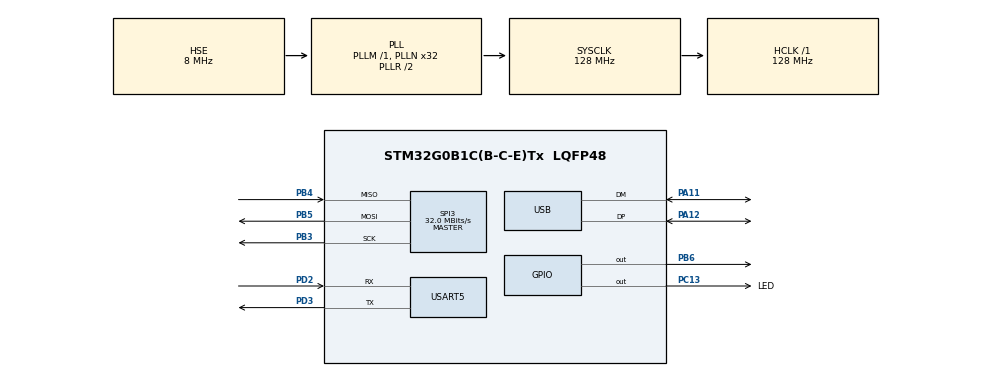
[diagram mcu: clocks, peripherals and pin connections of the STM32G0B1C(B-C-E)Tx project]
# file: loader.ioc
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Dma.MEMTOMEM.3.Direction=DMA_MEMORY_TO_MEMORY
Dma.MEMTOMEM.3.EventEnable=DISABLE
Dma.MEMTOMEM.3.Instance=DMA1_Channel5
Dma.MEMTOMEM.3.MemDataAlignment=DMA_MDATAALIGN_BYTE
Dma.MEMTOMEM.3.MemInc=DMA_MINC_ENABLE
Dma.MEMTOMEM.3.Mode=DMA_NORMAL
Dma.MEMTOMEM.3.PeriphDataAlignment=DMA_PDATAALIGN_BYTE
Dma.MEMTOMEM.3.PeriphInc=DMA_PINC_ENABLE
Dma.MEMTOMEM.3.Polarity=HAL_DMAMUX_REQ_GEN_RISING
Dma.MEMTOMEM.3.Priority=DMA_PRIORITY_LOW
Dma.MEMTOMEM.3.RequestNumber=1
Dma.MEMTOMEM.3.SignalID=NONE
Dma.MEMTOMEM.3.SyncEnable=DISABLE
Dma.MEMTOMEM.3.SyncPolarity=HAL_DMAMUX_SYNC_NO_EVENT
Dma.MEMTOMEM.3.SyncRequestNumber=1
Dma.MEMTOMEM.3.SyncSignalID=NONE
Dma.Request0=SPI3_RX
Dma.Request1=SPI3_TX
Dma.Request2=USART5_RX
Dma.Request3=MEMTOMEM
Dma.SPI3_RX.0.Direction=DMA_PERIPH_TO_MEMORY
Dma.SPI3_RX.0.EventEnable=DISABLE
Dma.SPI3_RX.0.Instance=DMA1_Channel1
Dma.SPI3_RX.0.MemDataAlignment=DMA_MDATAALIGN_BYTE
Dma.SPI3_RX.0.MemInc=DMA_MINC_ENABLE
Dma.SPI3_RX.0.Mode=DMA_NORMAL
Dma.SPI3_RX.0.PeriphDataAlignment=DMA_PDATAALIGN_BYTE
Dma.SPI3_RX.0.PeriphInc=DMA_PINC_DISABLE
Dma.SPI3_RX.0.Polarity=HAL_DMAMUX_REQ_GEN_RISING
Dma.SPI3_RX.0.Priority=DMA_PRIORITY_LOW
Dma.SPI3_RX.0.RequestNumber=1
Dma.SPI3_RX.0.SignalID=NONE
Dma.SPI3_RX.0.SyncEnable=DISABLE
Dma.SPI3_RX.0.SyncPolarity=HAL_DMAMUX_SYNC_NO_EVENT
Dma.SPI3_RX.0.SyncRequestNumber=1
Dma.SPI3_RX.0.SyncSignalID=NONE
Dma.SPI3_TX.1.Direction=DMA_MEMORY_TO_PERIPH
Dma.SPI3_TX.1.EventEnable=DISABLE
Dma.SPI3_TX.1.Instance=DMA1_Channel2
Dma.SPI3_TX.1.MemDataAlignment=DMA_MDATAALIGN_BYTE
Dma.SPI3_TX.1.MemInc=DMA_MINC_ENABLE
Dma.SPI3_TX.1.Mode=DMA_NORMAL
Dma.SPI3_TX.1.PeriphDataAlignment=DMA_PDATAALIGN_BYTE
Dma.SPI3_TX.1.PeriphInc=DMA_PINC_DISABLE
Dma.SPI3_TX.1.Polarity=HAL_DMAMUX_REQ_GEN_RISING
Dma.SPI3_TX.1.Priority=DMA_PRIORITY_LOW
Dma.SPI3_TX.1.RequestNumber=1
Dma.SPI3_TX.1.SignalID=NONE
Dma.SPI3_TX.1.SyncEnable=DISABLE
Dma.SPI3_TX.1.SyncPolarity=HAL_DMAMUX_SYNC_NO_EVENT
Dma.SPI3_TX.1.SyncRequestNumber=1
Dma.SPI3_TX.1.SyncSignalID=NONE
Dma.USART5_RX.2.Direction=DMA_PERIPH_TO_MEMORY
Dma.USART5_RX.2.EventEnable=DISABLE
Dma.USART5_RX.2.Instance=DMA1_Channel3
Dma.USART5_RX.2.MemDataAlignment=DMA_MDATAALIGN_BYTE
Dma.USART5_RX.2.MemInc=DMA_MINC_ENABLE
Dma.USART5_RX.2.Mode=DMA_NORMAL
Dma.USART5_RX.2.PeriphDataAlignment=DMA_PDATAALIGN_BYTE
Dma.USART5_RX.2.PeriphInc=DMA_PINC_DISABLE
Dma.USART5_RX.2.Polarity=HAL_DMAMUX_REQ_GEN_RISING
Dma.USART5_RX.2.Priority=DMA_PRIORITY_LOW
Dma.USART5_RX.2.RequestNumber=1
Dma.USART5_RX.2.SignalID=NONE
Dma.USART5_RX.2.SyncEnable=DISABLE
Dma.USART5_RX.2.SyncPolarity=HAL_DMAMUX_SYNC_NO_EVENT
Dma.USART5_RX.2.SyncRequestNumber=1
Dma.USART5_RX.2.SyncSignalID=NONE
Mcu.Family=STM32G0
Mcu.Name=STM32G0B1C(B-C-E)Tx
Mcu.Package=LQFP48
NVIC.DMA1_Ch4_7_DMA2_Ch1_5_DMAMUX1_OVR_IRQn=true\:0\:0\:false\:false\:true\:false\:true\:true
NVIC.DMA1_Channel1_IRQn=true\:0\:0\:false\:false\:true\:false\:true\:true
NVIC.DMA1_Channel2_3_IRQn=true\:0\:0\:false\:false\:true\:false\:true\:true
NVIC.FLASH_IRQn=true\:0\:0\:false\:false\:true\:true\:true\:true
NVIC.PVD_VDDIO2_IRQn=true\:0\:0\:false\:false\:true\:true\:true\:true
NVIC.RCC_IRQn=true\:0\:0\:false\:false\:true\:true\:false\:true
NVIC.SPI2_3_IRQn=true\:0\:0\:false\:false\:true\:true\:true\:true
NVIC.USART3_4_5_6_LPUART1_IRQn=true\:0\:0\:false\:false\:true\:true\:true\:true
NVIC.USB_UCPD1_2_IRQn=true\:0\:0\:false\:false\:true\:true\:true\:true
PA11\ [PA9].Mode=Device
PA11\ [PA9].Signal=USB_DM
PA12\ [PA10].Mode=Device
PA12\ [PA10].Signal=USB_DP
PA13.Mode=Serial_Wire
PA13.Signal=SYS_SWDIO
PA14-BOOT0.Mode=Serial_Wire
PA14-BOOT0.Signal=SYS_SWCLK
PB3.Mode=Full_Duplex_Master
PB3.Signal=SPI3_SCK
PB4.Mode=Full_Duplex_Master
PB4.Signal=SPI3_MISO
PB5.Mode=Full_Duplex_Master
PB5.Signal=SPI3_MOSI
PB6.PinState=GPIO_PIN_SET
PB6.Signal=GPIO_Output
PC13.GPIO_Label=LED
PC13.PinState=GPIO_PIN_SET
PC13.Signal=GPIO_Output
PC14-OSC32_IN\ (PC14).Mode=LSE-External-Oscillator
PC14-OSC32_IN\ (PC14).Signal=RCC_OSC32_IN
PC15-OSC32_OUT\ (PC15).Mode=LSE-External-Oscillator
PC15-OSC32_OUT\ (PC15).Signal=RCC_OSC32_OUT
PD2.Mode=Asynchronous
PD2.Signal=USART5_RX
PD3.Mode=Asynchronous
PD3.Signal=USART5_TX
PF0-OSC_IN\ (PF0).Mode=HSE-External-Oscillator
PF0-OSC_IN\ (PF0).Signal=RCC_OSC_IN
PF1-OSC_OUT\ (PF1).Mode=HSE-External-Oscillator
PF1-OSC_OUT\ (PF1).Signal=RCC_OSC_OUT
ProjectManager.HeapSize=0x200
ProjectManager.StackSize=0x2000
ProjectManager.TargetToolchain=MDK-ARM V5.32
RCC.ADCFreq_Value=128000000
RCC.AHBFreq_Value=128000000
RCC.CortexFreq_Value=128000000
RCC.EXTERNAL_CLOCK_VALUE=48000
RCC.HCLKFreq_Value=128000000
RCC.HSE_VALUE=8000000
RCC.HSI48_VALUE=48000000
RCC.HSI_VALUE=16000000
RCC.PLLN=32
RCC.PLLSourceVirtual=RCC_PLLSOURCE_HSE
RCC.SYSCLKFreq_VALUE=128000000
RCC.SYSCLKSource=RCC_SYSCLKSOURCE_PLLCLK
RCC.USBFreq_Value=48000000
RCC.VCOOutputFreq_Value=256000000
SPI3.BaudRatePrescaler=SPI_BAUDRATEPRESCALER_4
SPI3.CalculateBaudRate=32.0 MBits/s
SPI3.Direction=SPI_DIRECTION_2LINES
SPI3.Mode=SPI_MODE_MASTER
SPI3.VirtualType=VM_MASTER
USART5.VirtualMode-Asynchronous=VM_ASYNC
VP_SYS_VS_DBSignals.Mode=DisableDeadBatterySignals
board=custom

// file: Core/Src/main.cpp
/* USER CODE BEGIN Header */
/**
  ******************************************************************************
  * @file           : main.c
  * @brief          : Main program body
  ******************************************************************************
  * @attention
  *
  * Copyright (c) 2025 STMicroelectronics.
  * All rights reserved.
  *
  * This software is licensed under terms that can be found in the LICENSE file
  * in the root directory of this software component.
  * If no LICENSE file comes with this software, it is provided AS-IS.
  *
  ******************************************************************************
  */
/* USER CODE END Header */
#include "main.h"
#include "dma.h"
#include "spi.h"
#include "usart.h"
#include "usb_drd_fs.h"
#include "gpio.h"
#include "program.h"

void SystemClock_Config(void);

#define LED(x) HAL_GPIO_WritePin(LED_GPIO_Port, LED_Pin, (GPIO_PinState)x)
int main(void)
{

  /* MCU Configuration--------------------------------------------------------*/

  /* Reset of all peripherals, Initializes the Flash interface and the Systick. */
  HAL_Init();

  /* Configure the system clock */
  SystemClock_Config();

  /* Initialize all configured peripherals */
  MX_GPIO_Init();
  MX_DMA_Init();
  MX_USB_DRD_FS_PCD_Init();
  MX_SPI3_Init();
  MX_USART5_UART_Init();
  /* USER CODE BEGIN 2 */

  Init();
  Run();
  /* USER CODE END 2 */

  /* Infinite loop */

}

void SystemClock_Config(void)
{
  RCC_OscInitTypeDef RCC_OscInitStruct = {0};
  RCC_ClkInitTypeDef RCC_ClkInitStruct = {0};

  /** Configure the main internal regulator output voltage
  */
  HAL_PWREx_ControlVoltageScaling(PWR_REGULATOR_VOLTAGE_SCALE1);

  /** Initializes the RCC Oscillators according to the specified parameters
  * in the RCC_OscInitTypeDef structure.
  */
  RCC_OscInitStruct.OscillatorType = RCC_OSCILLATORTYPE_HSE|RCC_OSCILLATORTYPE_HSI48;
  RCC_OscInitStruct.HSEState = RCC_HSE_ON;
  RCC_OscInitStruct.HSI48State = RCC_HSI48_ON;
  RCC_OscInitStruct.PLL.PLLState = RCC_PLL_ON;
  RCC_OscInitStruct.PLL.PLLSource = RCC_PLLSOURCE_HSE;
  RCC_OscInitStruct.PLL.PLLM = RCC_PLLM_DIV1;
  RCC_OscInitStruct.PLL.PLLN = 32;
  RCC_OscInitStruct.PLL.PLLP = RCC_PLLP_DIV2;
  RCC_OscInitStruct.PLL.PLLQ = RCC_PLLQ_DIV2;
  RCC_OscInitStruct.PLL.PLLR = RCC_PLLR_DIV2;
  if (HAL_RCC_OscConfig(&RCC_OscInitStruct) != HAL_OK)
  {
    Error_Handler();
  }

  /** Initializes the CPU, AHB and APB buses clocks
  */
  RCC_ClkInitStruct.ClockType = RCC_CLOCKTYPE_HCLK|RCC_CLOCKTYPE_SYSCLK
                              |RCC_CLOCKTYPE_PCLK1;
  RCC_ClkInitStruct.SYSCLKSource = RCC_SYSCLKSOURCE_PLLCLK;
  RCC_ClkInitStruct.AHBCLKDivider = RCC_SYSCLK_DIV1;
  RCC_ClkInitStruct.APB1CLKDivider = RCC_HCLK_DIV1;

  if (HAL_RCC_ClockConfig(&RCC_ClkInitStruct, FLASH_LATENCY_2) != HAL_OK)
  {
    Error_Handler();
  }
}

void Error_Handler(void)
{
  __disable_irq();
  while (1)
  {
  }
}
